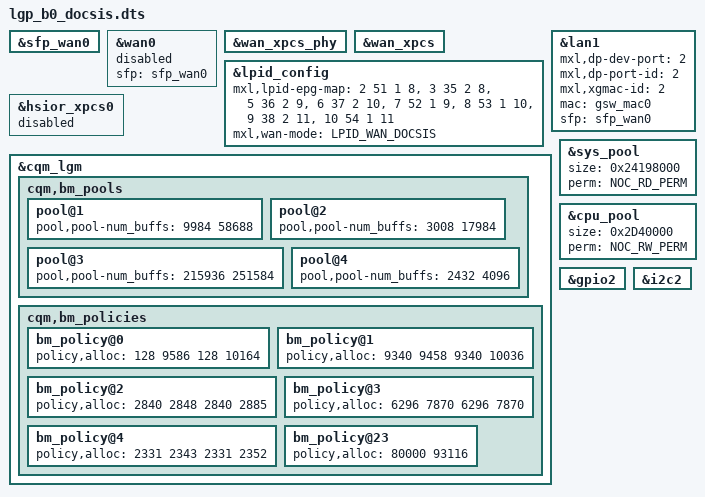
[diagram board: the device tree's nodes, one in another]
// SPDX-License-Identifier: GPL-2.0
/*
 * Copyright (C) 2021-2022 MaxLinear, Inc.
 *
 * This program is free software; you can redistribute it and/or modify it
 * under the terms of the GNU General Public License, as published by the Free
 * Software Foundation; either version 2 of the License, or (at your option)
 * any later version.
 *
 * This program is distributed in the hope that it will be useful, but WITHOUT
 * ANY WARRANTY; without even the implied warranty of MERCHANTABILITY or
 * FITNESS FOR A PARTICULAR PURPOSE.
 * See the GNU General Public License for more details.
 *
 * You should have received a copy of the GNU General Public License along
 * with this program; if not, see <http://www.gnu.org/licenses/>.
 */

/dts-v1/;

#include "lgp_b0.dts"

&sfp_wan0 {
	status = "okay";
};

&wan0 {
	status = "disabled";
};

&wan0 {
	sfp = <&sfp_wan0>;
};

&wan_xpcs_phy {
	status = "okay";
};

&wan_xpcs {
	status = "okay";
};

&lpid_config {
	mxl,lpid-epg-map = <2 51 1 8>,
				<3 35 2 8>,
				<5 36 2 9>,
				<6 37 2 10>,
				<7 52 1 9>,
				<8 53 1 10>,
				<9 38 2 11>,
				<10 54 1 11>;
};

&lan1 {
	mxl,dp-dev-port = <2>;
	mxl,dp-port-id = <2>;
	mxl,xgmac-id = <2>;
	mac = <&gsw_mac0>;
	sfp = <&sfp_wan0>;
	/delete-property/ phy;
};

&hsior_xpcs0 {
	status = "disabled";
};

&cqm_lgm {
	cqm,bm_pools {
		pool@1 {
			pool,pool-num_buffs = <9984 58688>;
		};
		pool@2 {
			pool,pool-num_buffs = <3008 17984>;
		};
		pool@3 {
			pool,pool-num_buffs = <215936 251584>;
		};
		pool@4 {
			pool,pool-num_buffs = <2432 4096>;
		};
	};
	cqm,bm_policies {
		/delete-node/ bm_policy@12;
		/delete-node/ bm_policy@13;
		/delete-node/ bm_policy@14;
		/delete-node/ bm_policy@15;
		/delete-node/ bm_policy@16;

		bm_policy@0 {
			policy,alloc = <128 9586 128 10164>;
		};
		bm_policy@1 {
			policy,alloc = <9340 9458 9340 10036>;
		};
		bm_policy@2 {
			policy,alloc = <2840 2848 2840 2885>;
		};
		bm_policy@3 {
			policy,alloc = <6296 7870 6296 7870>;
		};
		bm_policy@4 {
			policy,alloc = <2331 2343 2331 2352>;
		};
		bm_policy@23 {
			policy,alloc = <80000 93116>;
		};
	};
};

&sys_pool {
	size = <0x24198000>;
	perm = <NOC_RD_PERM>;
};

&cpu_pool {
	size = <0x2D40000>;
	perm = <NOC_RW_PERM>;
};

&gpio2 {
	/delete-node/ sfp_eth_tx_disable;
};

&i2c2 {
	status = "okay";
};

&lpid_config {
	mxl,wan-mode = <LPID_WAN_DOCSIS>;
};
